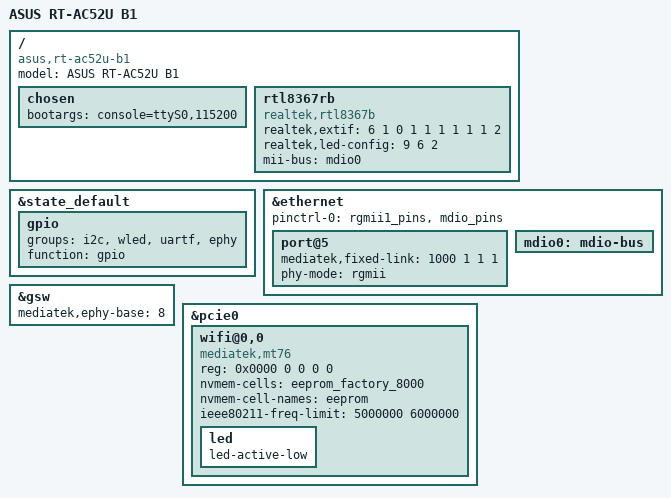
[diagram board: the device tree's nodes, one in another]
#include "mt7620a_asus_rt-ac5x.dtsi"

/ {
	compatible = "asus,rt-ac52u-b1", "ralink,mt7620a-soc";
	model = "ASUS RT-AC52U B1";

    chosen {
		bootargs = "console=ttyS0,115200";
	};

	rtl8367rb {
		compatible = "realtek,rtl8367b";
		realtek,extif = <6 1 0 1 1 1 1 1 1 2>;
        realtek,led-config = <9 6 2>;	/* group 0: 10/100/1000+act, 1: 1000+act, 2: link+act */
		mii-bus = <&mdio0>;
	};
};

&state_default {
	gpio {
		groups = "i2c", "wled", "uartf", "ephy";
		function = "gpio";
	};
};

&ethernet {
	pinctrl-names = "default";
	pinctrl-0 = <&rgmii1_pins &mdio_pins>;

	port@5 {
		status = "okay";
		mediatek,fixed-link = <1000 1 1 1>;
		phy-mode = "rgmii";
	};

	mdio0: mdio-bus {
		status = "okay";
	};
};

&gsw {
	mediatek,ephy-base = /bits/ 8 <8>;
};

&pcie0 {
	wifi@0,0 {
		compatible = "mediatek,mt76";
		reg = <0x0000 0 0 0 0>;
		nvmem-cells = <&eeprom_factory_8000>;
		nvmem-cell-names = "eeprom";
		ieee80211-freq-limit = <5000000 6000000>;

		led {
			led-active-low;
		};
	};
};
